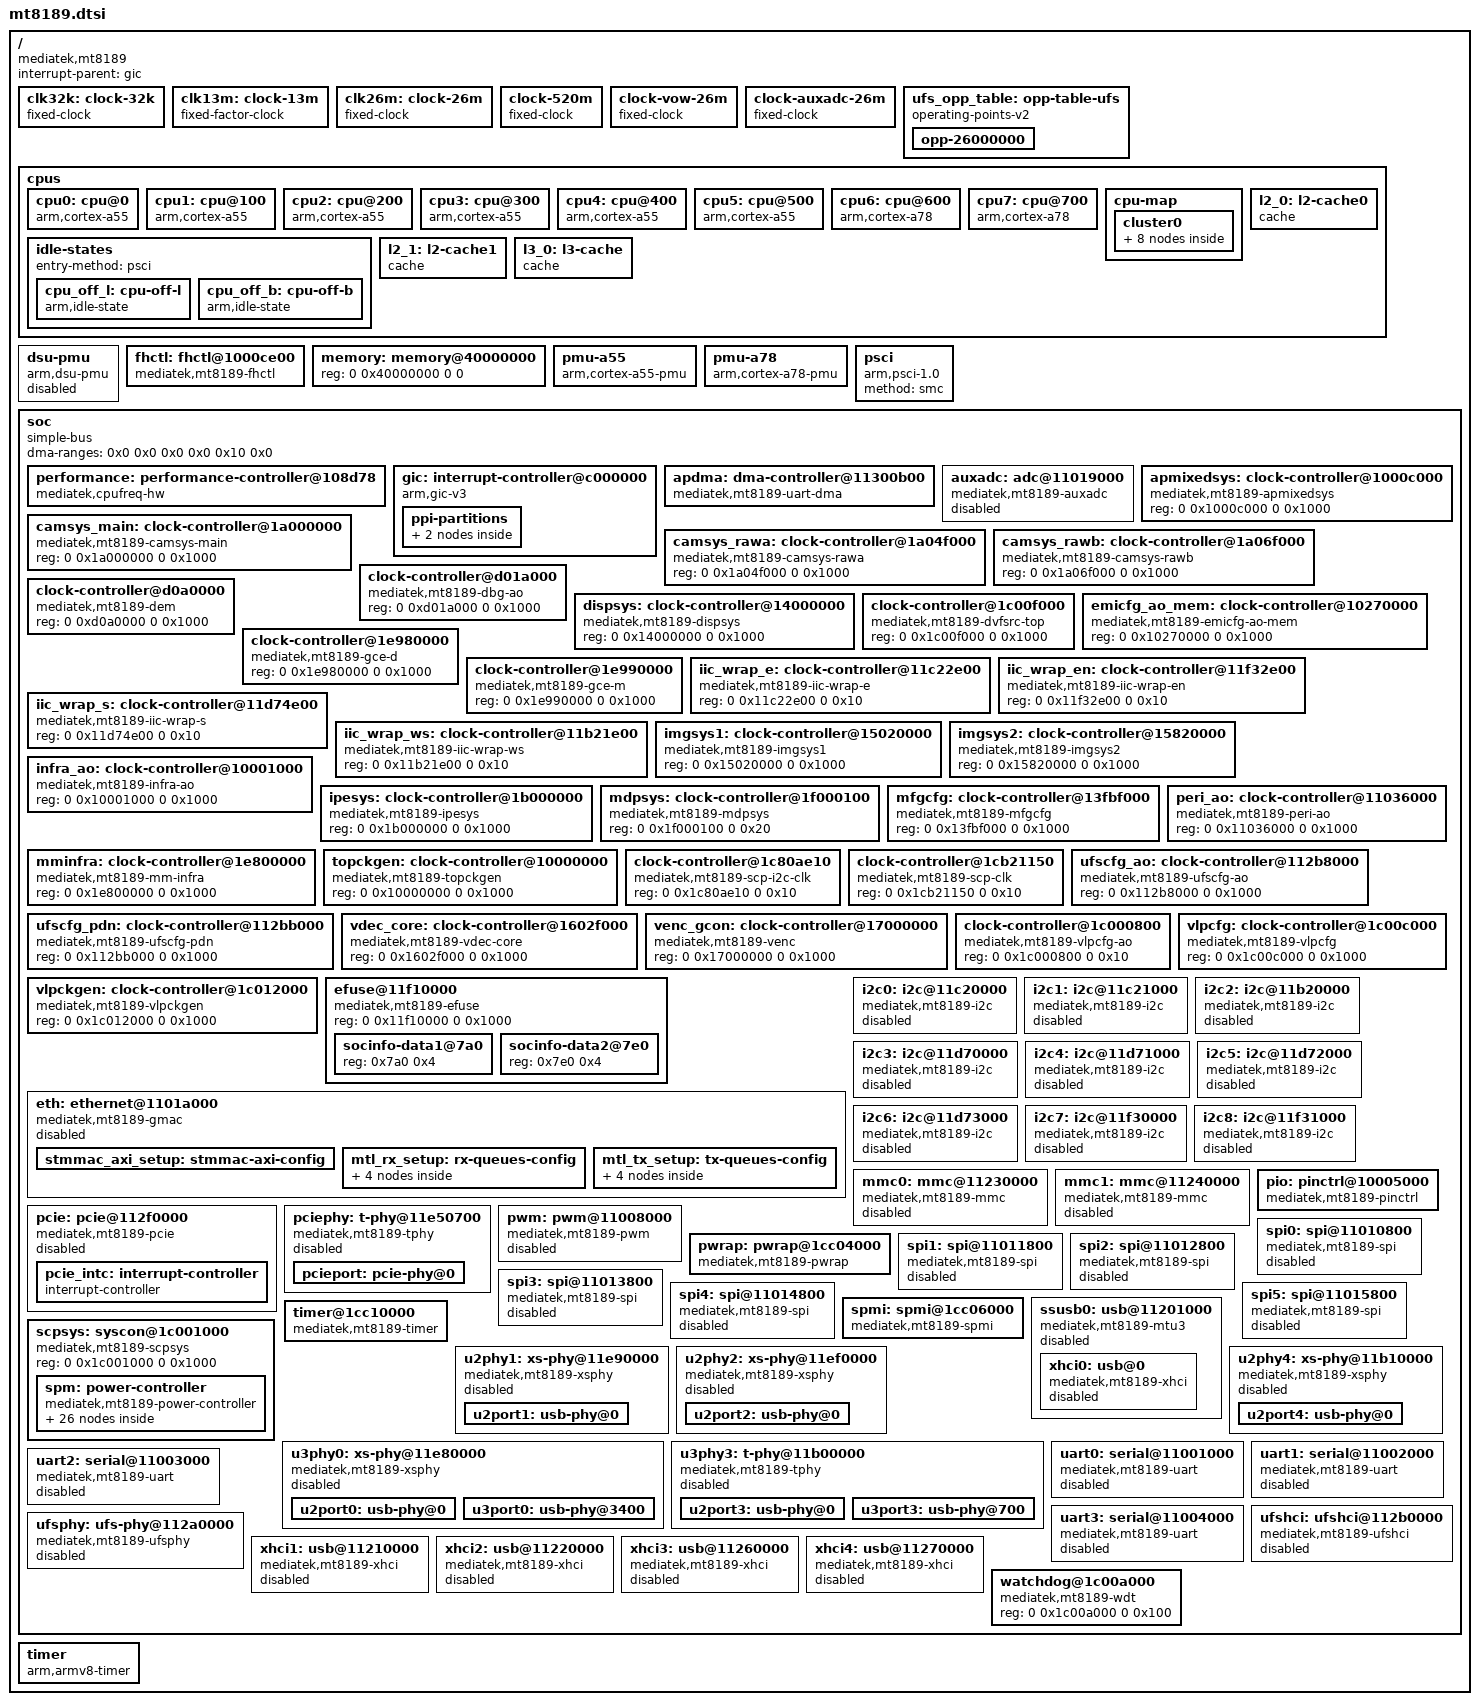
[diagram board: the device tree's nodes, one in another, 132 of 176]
// SPDX-License-Identifier: (GPL-2.0 OR MIT)
/*
 * Copyright (c) 2025 MediaTek Inc.
 *
 * Copyright (c) 2025 Collabora Ltd.
 * Author: Louis-Alexis Eyraud <louisalexis.eyraud@collabora.com>
 */

#include <dt-bindings/clock/mediatek,mt8189-clk.h>
#include <dt-bindings/interrupt-controller/arm-gic.h>
#include <dt-bindings/interrupt-controller/irq.h>
#include <dt-bindings/power/mediatek,mt8189-power.h>
#include <dt-bindings/phy/phy.h>
#include <dt-bindings/reset/mediatek,mt8189-resets.h>

/ {
	compatible = "mediatek,mt8189";
	interrupt-parent = <&gic>;
	#address-cells = <2>;
	#size-cells = <2>;

	clk32k: clock-32k {
		compatible = "fixed-clock";
		#clock-cells = <0>;
		clock-frequency = <32000>;
		clock-output-names = "clk32k";
	};

	clk13m: clock-13m {
		compatible = "fixed-factor-clock";
		#clock-cells = <0>;
		clocks = <&clk26m>;
		clock-mult = <1>;
		clock-div = <2>;
		clock-output-names = "clk13m";
	};

	clk26m: clock-26m {
		compatible = "fixed-clock";
		#clock-cells = <0>;
		clock-frequency = <26000000>;
		clock-output-names = "clk26m";
	};

	clock-520m {
		compatible = "fixed-clock";
		#clock-cells = <0>;
		clock-frequency = <520000000>;
		clock-output-names = "ulposc";
	};

	clock-vow-26m {
		compatible = "fixed-clock";
		#clock-cells = <0>;
		clock-frequency = <26000000>;
		clock-output-names = "vowpll";
	};

	clock-auxadc-26m {
		compatible = "fixed-clock";
		#clock-cells = <0>;
		clock-frequency = <26000000>;
		clock-output-names = "aud_adc_ext";
	};

	ufs_opp_table: opp-table-ufs {
		compatible = "operating-points-v2";

		opp-26000000 {
			opp-hz = /bits/ 64 <26000000>, /bits/ 64 <0>,
				 /bits/ 64 <0>, /bits/ 64 <0>, /bits/ 64 <0>,
				 /bits/ 64 <0>, /bits/ 64 <0>, /bits/ 64 <0>,
				 /bits/ 64 <0>, /bits/ 64 <0>, /bits/ 64 <0>,
				 /bits/ 64 <0>, /bits/ 64 <0>, /bits/ 64 <0>,
				 /bits/ 64 <0>, /bits/ 64 <0>;
		};
	};

	cpus {
		#address-cells = <1>;
		#size-cells = <0>;

		cpu0: cpu@0 {
			device_type = "cpu";
			compatible = "arm,cortex-a55";
			reg = <0x000>;
			enable-method = "psci";
			capacity-dmips-mhz = <282>;
			cpu-idle-states = <&cpu_off_l>;
			i-cache-size = <32768>;
			i-cache-line-size = <64>;
			i-cache-sets = <128>;
			d-cache-size = <32768>;
			d-cache-line-size = <64>;
			d-cache-sets = <128>;
			next-level-cache = <&l2_0>;
			performance-domains = <&performance 0>;
			#cooling-cells = <2>;
		};

		cpu1: cpu@100 {
			device_type = "cpu";
			compatible = "arm,cortex-a55";
			reg = <0x100>;
			enable-method = "psci";
			capacity-dmips-mhz = <282>;
			cpu-idle-states = <&cpu_off_l>;
			i-cache-size = <32768>;
			i-cache-line-size = <64>;
			i-cache-sets = <128>;
			d-cache-size = <32768>;
			d-cache-line-size = <64>;
			d-cache-sets = <128>;
			next-level-cache = <&l2_0>;
			performance-domains = <&performance 0>;
			#cooling-cells = <2>;
		};

		cpu2: cpu@200 {
			device_type = "cpu";
			compatible = "arm,cortex-a55";
			reg = <0x200>;
			enable-method = "psci";
			capacity-dmips-mhz = <282>;
			cpu-idle-states = <&cpu_off_l>;
			i-cache-size = <32768>;
			i-cache-line-size = <64>;
			i-cache-sets = <128>;
			d-cache-size = <32768>;
			d-cache-line-size = <64>;
			d-cache-sets = <128>;
			next-level-cache = <&l2_0>;
			performance-domains = <&performance 0>;
			#cooling-cells = <2>;
		};

		cpu3: cpu@300 {
			device_type = "cpu";
			compatible = "arm,cortex-a55";
			reg = <0x300>;
			enable-method = "psci";
			capacity-dmips-mhz = <282>;
			cpu-idle-states = <&cpu_off_l>;
			i-cache-size = <32768>;
			i-cache-line-size = <64>;
			i-cache-sets = <128>;
			d-cache-size = <32768>;
			d-cache-line-size = <64>;
			d-cache-sets = <128>;
			next-level-cache = <&l2_0>;
			performance-domains = <&performance 0>;
			#cooling-cells = <2>;
		};

		cpu4: cpu@400 {
			device_type = "cpu";
			compatible = "arm,cortex-a55";
			reg = <0x400>;
			enable-method = "psci";
			capacity-dmips-mhz = <282>;
			cpu-idle-states = <&cpu_off_l>;
			i-cache-size = <32768>;
			i-cache-line-size = <64>;
			i-cache-sets = <128>;
			d-cache-size = <32768>;
			d-cache-line-size = <64>;
			d-cache-sets = <128>;
			next-level-cache = <&l2_0>;
			performance-domains = <&performance 0>;
			#cooling-cells = <2>;
		};

		cpu5: cpu@500 {
			device_type = "cpu";
			compatible = "arm,cortex-a55";
			reg = <0x500>;
			enable-method = "psci";
			capacity-dmips-mhz = <282>;
			cpu-idle-states = <&cpu_off_l>;
			i-cache-size = <32768>;
			i-cache-line-size = <64>;
			i-cache-sets = <128>;
			d-cache-size = <32768>;
			d-cache-line-size = <64>;
			d-cache-sets = <128>;
			next-level-cache = <&l2_0>;
			performance-domains = <&performance 0>;
			#cooling-cells = <2>;
		};

		cpu6: cpu@600 {
			device_type = "cpu";
			compatible = "arm,cortex-a78";
			reg = <0x600>;
			enable-method = "psci";
			capacity-dmips-mhz = <1024>;
			cpu-idle-states = <&cpu_off_b>;
			i-cache-size = <65536>;
			i-cache-line-size = <64>;
			i-cache-sets = <256>;
			d-cache-size = <65536>;
			d-cache-line-size = <64>;
			d-cache-sets = <256>;
			next-level-cache = <&l2_1>;
			performance-domains = <&performance 1>;
			#cooling-cells = <2>;
		};

		cpu7: cpu@700 {
			device_type = "cpu";
			compatible = "arm,cortex-a78";
			reg = <0x700>;
			enable-method = "psci";
			capacity-dmips-mhz = <1024>;
			cpu-idle-states = <&cpu_off_b>;
			i-cache-size = <65536>;
			i-cache-line-size = <64>;
			i-cache-sets = <256>;
			d-cache-size = <65536>;
			d-cache-line-size = <64>;
			d-cache-sets = <256>;
			next-level-cache = <&l2_1>;
			performance-domains = <&performance 1>;
			#cooling-cells = <2>;
		};

		cpu-map {
			cluster0 {
				core0 {
					cpu = <&cpu0>;
				};

				core1 {
					cpu = <&cpu1>;
				};

				core2 {
					cpu = <&cpu2>;
				};

				core3 {
					cpu = <&cpu3>;
				};

				core4 {
					cpu = <&cpu4>;
				};

				core5 {
					cpu = <&cpu5>;
				};

				core6 {
					cpu = <&cpu6>;
				};

				core7 {
					cpu = <&cpu7>;
				};
			};
		};

		idle-states {
			entry-method = "psci";

			cpu_off_l: cpu-off-l {
				compatible = "arm,idle-state";
				arm,psci-suspend-param = <0x00010000>;
				local-timer-stop;
				entry-latency-us = <25>;
				exit-latency-us = <57>;
				min-residency-us = <5700>;
			};

			cpu_off_b: cpu-off-b {
				compatible = "arm,idle-state";
				arm,psci-suspend-param = <0x00010000>;
				local-timer-stop;
				entry-latency-us = <35>;
				exit-latency-us = <82>;
				min-residency-us = <1890>;
			};
		};

		l2_0: l2-cache0 {
			compatible = "cache";
			cache-level = <2>;
			cache-size = <131072>;
			cache-line-size = <64>;
			cache-sets = <512>;
			next-level-cache = <&l3_0>;
			cache-unified;
		};

		l2_1: l2-cache1 {
			compatible = "cache";
			cache-level = <2>;
			cache-size = <262144>;
			cache-line-size = <64>;
			cache-sets = <512>;
			next-level-cache = <&l3_0>;
			cache-unified;
		};

		l3_0: l3-cache {
			compatible = "cache";
			cache-level = <3>;
			cache-size = <1048576>;
			cache-line-size = <64>;
			cache-sets = <2048>;
			cache-unified;
		};
	};

	dsu-pmu {
		compatible = "arm,dsu-pmu";
		interrupts = <GIC_SPI 18 IRQ_TYPE_LEVEL_HIGH 0>;
		cpus = <&cpu0>, <&cpu1>, <&cpu2>, <&cpu3>,
		       <&cpu4>, <&cpu5>, <&cpu6>, <&cpu7>;
		status = "fail";
	};

	fhctl: fhctl@1000ce00 {
		compatible = "mediatek,mt8189-fhctl";
		clocks = <&apmixedsys CLK_APMIXED_APUPLL>,
			 <&apmixedsys CLK_APMIXED_APUPLL2>,
			 <&apmixedsys CLK_APMIXED_ARMPLL_LL>,
			 <&apmixedsys CLK_APMIXED_ARMPLL_BL>,
			 <&apmixedsys CLK_APMIXED_CCIPLL>,
			 <&apmixedsys CLK_APMIXED_EMIPLL>,
			 <&apmixedsys CLK_APMIXED_MAINPLL>,
			 <&apmixedsys CLK_APMIXED_MFGPLL>,
			 <&apmixedsys CLK_APMIXED_MMPLL>,
			 <&apmixedsys CLK_APMIXED_MSDCPLL>,
			 <&apmixedsys CLK_APMIXED_TVDPLL1>,
			 <&apmixedsys CLK_APMIXED_TVDPLL2>,
			 <&apmixedsys CLK_APMIXED_UFSPLL>;
		reg = <0 0x1000ce00 0 0x200>;
		status = "okay";
	};

	memory: memory@40000000 {
		device_type = "memory";
		/* This memory size is filled in by the bootloader */
		reg = <0 0x40000000 0 0>;
	};

	pmu-a55 {
		compatible = "arm,cortex-a55-pmu";
		interrupt-parent = <&gic>;
		interrupts = <GIC_PPI 7 IRQ_TYPE_LEVEL_HIGH &ppi_cluster0>;
	};

	pmu-a78 {
		compatible = "arm,cortex-a78-pmu";
		interrupt-parent = <&gic>;
		interrupts = <GIC_PPI 7 IRQ_TYPE_LEVEL_HIGH &ppi_cluster1>;
	};

	psci {
		compatible = "arm,psci-1.0";
		method = "smc";
	};

	soc {
		compatible = "simple-bus";
		#address-cells = <2>;
		#size-cells = <2>;
		ranges;
		dma-ranges = <0x0 0x0 0x0 0x0 0x10 0x0>;

		performance: performance-controller@108d78 {
			compatible = "mediatek,cpufreq-hw";
			reg = <0 0x00108d78 0 0x120>, <0 0x00108e98 0 0x120>;
			#performance-domain-cells = <1>;
		};

		gic: interrupt-controller@c000000 {
			compatible = "arm,gic-v3";
			reg = <0 0xc000000 0 0x40000>, /* distributor */
			      <0 0xc040000 0 0x200000>; /* redistributor */
			interrupt-parent = <&gic>;
			interrupts = <GIC_PPI 9 IRQ_TYPE_LEVEL_HIGH 0>;
			interrupt-controller;
			#interrupt-cells = <4>;
			#redistributor-regions = <1>;

			ppi-partitions {
				ppi_cluster0: interrupt-partition-0 {
					affinity = <&cpu0 &cpu1 &cpu2 &cpu3 &cpu4 &cpu5>;
				};

				ppi_cluster1: interrupt-partition-1 {
					affinity = <&cpu6 &cpu7>;
				};
			};
		};

		apdma: dma-controller@11300b00 {
			compatible = "mediatek,mt8189-uart-dma", "mediatek,mt6985-uart-dma";
			reg = <0 0x11300b00 0 0x80>,
			      <0 0x11300b80 0 0x80>,
			      <0 0x11300c00 0 0x80>,
			      <0 0x11300c80 0 0x80>,
			      <0 0x11300d00 0 0x80>,
			      <0 0x11300d80 0 0x80>,
			      <0 0x11300e00 0 0x80>,
			      <0 0x11300e80 0 0x80>;
			interrupts = <GIC_SPI 432 IRQ_TYPE_LEVEL_HIGH 0>,
				     <GIC_SPI 433 IRQ_TYPE_LEVEL_HIGH 0>,
				     <GIC_SPI 434 IRQ_TYPE_LEVEL_HIGH 0>,
				     <GIC_SPI 435 IRQ_TYPE_LEVEL_HIGH 0>,
				     <GIC_SPI 436 IRQ_TYPE_LEVEL_HIGH 0>,
				     <GIC_SPI 437 IRQ_TYPE_LEVEL_HIGH 0>,
				     <GIC_SPI 438 IRQ_TYPE_LEVEL_HIGH 0>,
				     <GIC_SPI 439 IRQ_TYPE_LEVEL_HIGH 0>;
			clocks = <&peri_ao CLK_PERAO_DMA_B>;
			clock-names = "apdma";
			dma-requests = <8>;
			#dma-cells = <1>;
		};

		auxadc: adc@11019000 {
			compatible = "mediatek,mt8189-auxadc", "mediatek,mt8173-auxadc";
			reg = <0 0x11019000 0 0x1000>;
			clocks = <&peri_ao CLK_PERAO_AUXADC_26M>;
			clock-names = "main";
			#io-channel-cells = <1>;
			status = "disabled";
		};

		apmixedsys: clock-controller@1000c000 {
			compatible = "mediatek,mt8189-apmixedsys", "syscon";
			reg = <0 0x1000c000 0 0x1000>;
			#clock-cells = <1>;
		};

		camsys_main: clock-controller@1a000000 {
			compatible = "mediatek,mt8189-camsys-main";
			reg = <0 0x1a000000 0 0x1000>;
			#clock-cells = <1>;
		};

		camsys_rawa: clock-controller@1a04f000 {
			compatible = "mediatek,mt8189-camsys-rawa";
			reg = <0 0x1a04f000 0 0x1000>;
			#clock-cells = <1>;
		};

		camsys_rawb: clock-controller@1a06f000 {
			compatible = "mediatek,mt8189-camsys-rawb";
			reg = <0 0x1a06f000 0 0x1000>;
			#clock-cells = <1>;
		};

		clock-controller@d01a000 {
			compatible = "mediatek,mt8189-dbg-ao";
			reg = <0 0xd01a000 0 0x1000>;
			#clock-cells = <1>;
		};

		clock-controller@d0a0000 {
			compatible = "mediatek,mt8189-dem";
			reg = <0 0xd0a0000 0 0x1000>;
			#clock-cells = <1>;
		};

		dispsys: clock-controller@14000000 {
			compatible = "mediatek,mt8189-dispsys";
			reg = <0 0x14000000 0 0x1000>;
			#clock-cells = <1>;
		};

		clock-controller@1c00f000 {
			compatible = "mediatek,mt8189-dvfsrc-top";
			reg = <0 0x1c00f000 0 0x1000>;
			#clock-cells = <1>;
		};

		emicfg_ao_mem: clock-controller@10270000 {
			compatible = "mediatek,mt8189-emicfg-ao-mem", "syscon";
			reg = <0 0x10270000 0 0x1000>;
			#clock-cells = <1>;
		};

		clock-controller@1e980000 {
			compatible = "mediatek,mt8189-gce-d";
			reg = <0 0x1e980000 0 0x1000>;
			#clock-cells = <1>;
		};

		clock-controller@1e990000 {
			compatible = "mediatek,mt8189-gce-m";
			reg = <0 0x1e990000 0 0x1000>;
			#clock-cells = <1>;
		};

		iic_wrap_e: clock-controller@11c22e00 {
			compatible = "mediatek,mt8189-iic-wrap-e";
			reg = <0 0x11c22e00 0 0x10>;
			#clock-cells = <1>;
		};

		iic_wrap_en: clock-controller@11f32e00 {
			compatible = "mediatek,mt8189-iic-wrap-en";
			reg = <0 0x11f32e00 0 0x10>;
			#clock-cells = <1>;
		};

		iic_wrap_s: clock-controller@11d74e00 {
			compatible = "mediatek,mt8189-iic-wrap-s";
			reg = <0 0x11d74e00 0 0x10>;
			#clock-cells = <1>;
		};

		iic_wrap_ws: clock-controller@11b21e00 {
			compatible = "mediatek,mt8189-iic-wrap-ws";
			reg = <0 0x11b21e00 0 0x10>;
			#clock-cells = <1>;
		};

		imgsys1: clock-controller@15020000 {
			compatible = "mediatek,mt8189-imgsys1";
			reg = <0 0x15020000 0 0x1000>;
			#clock-cells = <1>;
		};

		imgsys2: clock-controller@15820000 {
			compatible = "mediatek,mt8189-imgsys2";
			reg = <0 0x15820000 0 0x1000>;
			#clock-cells = <1>;
		};

		infra_ao: clock-controller@10001000 {
			compatible = "mediatek,mt8189-infra-ao", "syscon";
			reg = <0 0x10001000 0 0x1000>;
			#clock-cells = <1>;
		};

		ipesys: clock-controller@1b000000 {
			compatible = "mediatek,mt8189-ipesys";
			reg = <0 0x1b000000 0 0x1000>;
			#clock-cells = <1>;
		};

		mdpsys: clock-controller@1f000100 {
			compatible = "mediatek,mt8189-mdpsys";
			reg = <0 0x1f000100 0 0x20>;
			#clock-cells = <1>;
		};

		mfgcfg: clock-controller@13fbf000 {
			compatible = "mediatek,mt8189-mfgcfg";
			reg = <0 0x13fbf000 0 0x1000>;
			#clock-cells = <1>;
		};

		mminfra: clock-controller@1e800000 {
			compatible = "mediatek,mt8189-mm-infra";
			reg = <0 0x1e800000 0 0x1000>;
			#clock-cells = <1>;
		};

		peri_ao: clock-controller@11036000 {
			compatible = "mediatek,mt8189-peri-ao", "syscon";
			reg = <0 0x11036000 0 0x1000>;
			#clock-cells = <1>;
			#reset-cells = <1>;
		};

		topckgen: clock-controller@10000000 {
			compatible = "mediatek,mt8189-topckgen", "syscon";
			reg = <0 0x10000000 0 0x1000>;
			#clock-cells = <1>;
		};

		clock-controller@1c80ae10 {
			compatible = "mediatek,mt8189-scp-i2c-clk";
			reg = <0 0x1c80ae10 0 0x10>;
			#clock-cells = <1>;
		};

		clock-controller@1cb21150 {
			compatible = "mediatek,mt8189-scp-clk";
			reg = <0 0x1cb21150 0 0x10>;
			#clock-cells = <1>;
		};

		ufscfg_ao: clock-controller@112b8000 {
			compatible = "mediatek,mt8189-ufscfg-ao";
			reg = <0 0x112b8000 0 0x1000>;
			#clock-cells = <1>;
			#reset-cells = <1>;
		};

		ufscfg_pdn: clock-controller@112bb000 {
			compatible = "mediatek,mt8189-ufscfg-pdn";
			reg = <0 0x112bb000 0 0x1000>;
			#clock-cells = <1>;
			#reset-cells = <1>;
		};

		vdec_core: clock-controller@1602f000 {
			compatible = "mediatek,mt8189-vdec-core";
			reg = <0 0x1602f000 0 0x1000>;
			#clock-cells = <1>;
		};

		venc_gcon: clock-controller@17000000 {
			compatible = "mediatek,mt8189-venc";
			reg = <0 0x17000000 0 0x1000>;
			#clock-cells = <1>;
		};

		clock-controller@1c000800 {
			compatible = "mediatek,mt8189-vlpcfg-ao";
			reg = <0 0x1c000800 0 0x10>;
			#clock-cells = <1>;
		};

		vlpcfg: clock-controller@1c00c000 {
			compatible = "mediatek,mt8189-vlpcfg";
			reg = <0 0x1c00c000 0 0x1000>;
			#clock-cells = <1>;
		};

		vlpckgen: clock-controller@1c012000 {
			compatible = "mediatek,mt8189-vlpckgen", "syscon";
			reg = <0 0x1c012000 0 0x1000>;
			#clock-cells = <1>;
		};

		efuse@11f10000 {
			compatible = "mediatek,mt8189-efuse", "mediatek,mt8186-efuse";
			reg = <0 0x11f10000 0 0x1000>;
			#address-cells = <1>;
			#size-cells = <1>;

			socinfo-data1@7a0 {
				reg = <0x7a0 0x4>;
			};

			socinfo-data2@7e0 {
				reg = <0x7e0 0x4>;
			};
		};

		eth: ethernet@1101a000 {
			compatible = "mediatek,mt8189-gmac", "snps,dwmac-5.10a";
			reg = <0 0x1101a000 0 0x4000>;
			assigned-clocks = <&topckgen CLK_TOP_ETH_250M_SEL>,
					  <&topckgen CLK_TOP_ETH_62P4M_PTP_SEL>,
					  <&topckgen CLK_TOP_ETH_50M_RMII_SEL>;
			assigned-clock-parents = <&topckgen CLK_TOP_ETHPLL_D2>,
						 <&topckgen CLK_TOP_ETHPLL_D8>,
						 <&topckgen CLK_TOP_ETHPLL_D10>;
			clocks = <&topckgen CLK_TOP_ETH_250M_SEL>,
				 <&topckgen CLK_TOP_ETH_62P4M_PTP_SEL>,
				 <&topckgen CLK_TOP_ETH_50M_RMII_SEL>;
			clock-names = "mac_main", "ptp_ref", "rmii_internal";
			interrupts = <GIC_SPI 475 IRQ_TYPE_LEVEL_HIGH 0>;
			interrupt-names = "macirq";
			power-domains = <&spm MT8189_POWER_DOMAIN_PCIE>;
			mediatek,pericfg = <&peri_ao>;
			snps,axi-config = <&stmmac_axi_setup>;
			snps,mtl-rx-config = <&mtl_rx_setup>;
			snps,mtl-tx-config = <&mtl_tx_setup>;
			snps,txpbl = <16>;
			snps,rxpbl = <16>;
			snps,clk-csr = <0>;
			status = "disabled";

			stmmac_axi_setup: stmmac-axi-config {
				snps,blen = <0 0 0 0 16 8 4>;
				snps,rd_osr_lmt = <0x7>;
				snps,wr_osr_lmt = <0x7>;
			};

			mtl_rx_setup: rx-queues-config {
				snps,rx-queues-to-use = <4>;
				snps,rx-sched-sp;

				queue0 {
					snps,dcb-algorithm;
					snps,map-to-dma-channel = <0x0>;
				};

				queue1 {
					snps,dcb-algorithm;
					snps,map-to-dma-channel = <0x0>;
				};

				queue2 {
					snps,dcb-algorithm;
					snps,map-to-dma-channel = <0x0>;
				};

				queue3 {
					snps,dcb-algorithm;
					snps,map-to-dma-channel = <0x0>;
				};
			};

			mtl_tx_setup: tx-queues-config {
				snps,tx-queues-to-use = <4>;
				snps,tx-sched-wrr;

				queue0 {
					snps,dcb-algorithm;
					snps,priority = <0x0>;
					snps,weight = <0x10>;
				};

				queue1 {
					snps,dcb-algorithm;
					snps,priority = <0x1>;
					snps,weight = <0x11>;
				};

				queue2 {
					snps,dcb-algorithm;
					snps,priority = <0x2>;
					snps,weight = <0x12>;
				};

				queue3 {
					snps,dcb-algorithm;
					snps,priority = <0x3>;
					snps,weight = <0x13>;
				};
			};
		};

		i2c0: i2c@11c20000 {
			compatible = "mediatek,mt8189-i2c", "mediatek,mt8188-i2c";
			reg = <0 0x11c20000 0 0x1000>, <0 0x11300200 0 0x80>;
			#address-cells = <1>;
			clock-div = <1>;
			clocks = <&iic_wrap_e CLK_IMPE_I2C0>, <&peri_ao CLK_PERAO_DMA_B>;
			clock-names = "main", "dma";
			interrupts = <GIC_SPI 274 IRQ_TYPE_LEVEL_HIGH 0>;
			#size-cells = <0>;
			status = "disabled";
		};

		i2c1: i2c@11c21000 {
			compatible = "mediatek,mt8189-i2c", "mediatek,mt8188-i2c";
			reg = <0 0x11c21000 0 0x1000>, <0 0x11300300 0 0x80>;
			#address-cells = <1>;
			clock-div = <1>;
			clocks = <&iic_wrap_e CLK_IMPE_I2C1>, <&peri_ao CLK_PERAO_DMA_B>;
			clock-names = "main", "dma";
			interrupts = <GIC_SPI 275 IRQ_TYPE_LEVEL_HIGH 0>;
			#size-cells = <0>;
			status = "disabled";
		};

		i2c2: i2c@11b20000 {
			compatible = "mediatek,mt8189-i2c", "mediatek,mt8188-i2c";
			reg = <0 0x11b20000 0 0x1000>, <0 0x11300400 0 0x80>;
			#address-cells = <1>;
			clock-div = <1>;
			clocks = <&iic_wrap_ws CLK_IMPWS_I2C2>, <&peri_ao CLK_PERAO_DMA_B>;
			clock-names = "main", "dma";
			interrupts = <GIC_SPI 276 IRQ_TYPE_LEVEL_HIGH 0>;
			#size-cells = <0>;
			status = "disabled";
		};

		i2c3: i2c@11d70000 {
			compatible = "mediatek,mt8189-i2c", "mediatek,mt8188-i2c";
			reg = <0 0x11d70000 0 0x1000>, <0 0x11300500 0 0x80>;
			#address-cells = <1>;
			clock-div = <1>;
			clocks = <&iic_wrap_s CLK_IMPS_I2C3>, <&peri_ao CLK_PERAO_DMA_B>;
			clock-names = "main", "dma";
			interrupts = <GIC_SPI 277 IRQ_TYPE_LEVEL_HIGH 0>;
			#size-cells = <0>;
			status = "disabled";
		};

		i2c4: i2c@11d71000 {
			compatible = "mediatek,mt8189-i2c", "mediatek,mt8188-i2c";
			reg = <0 0x11d71000 0 0x1000>, <0 0x11300600 0 0x80>;
			#address-cells = <1>;
			clock-div = <1>;
			clocks = <&iic_wrap_s CLK_IMPS_I2C4>, <&peri_ao CLK_PERAO_DMA_B>;
			clock-names = "main", "dma";
			interrupts = <GIC_SPI 208 IRQ_TYPE_LEVEL_HIGH 0>;
			#size-cells = <0>;
			status = "disabled";
		};

		i2c5: i2c@11d72000 {
			compatible = "mediatek,mt8189-i2c", "mediatek,mt8188-i2c";
			reg = <0 0x11d72000 0 0x1000>, <0 0x11300700 0 0x80>;
			#address-cells = <1>;
			clock-div = <1>;
			clocks = <&iic_wrap_s CLK_IMPS_I2C5>, <&peri_ao CLK_PERAO_DMA_B>;
			clock-names = "main", "dma";
			interrupts = <GIC_SPI 209 IRQ_TYPE_LEVEL_HIGH 0>;
			#size-cells = <0>;
			status = "disabled";
		};

		i2c6: i2c@11d73000 {
			compatible = "mediatek,mt8189-i2c", "mediatek,mt8188-i2c";
			reg = <0 0x11d73000 0 0x1000>, <0 0x11300800 0 0x80>;
			#address-cells = <1>;
			clock-div = <1>;
			clocks = <&iic_wrap_s CLK_IMPS_I2C6>, <&peri_ao CLK_PERAO_DMA_B>;
			clock-names = "main", "dma";
			interrupts = <GIC_SPI 210 IRQ_TYPE_LEVEL_HIGH 0>;
			#size-cells = <0>;
			status = "disabled";
		};

		i2c7: i2c@11f30000 {
			compatible = "mediatek,mt8189-i2c", "mediatek,mt8188-i2c";
			reg = <0 0x11f30000 0 0x1000>, <0 0x11300900 0 0x80>;
			#address-cells = <1>;
			clock-div = <1>;
			clocks = <&iic_wrap_en CLK_IMPEN_I2C7>, <&peri_ao CLK_PERAO_DMA_B>;
			clock-names = "main", "dma";
			interrupts = <GIC_SPI 211 IRQ_TYPE_LEVEL_HIGH 0>;
			#size-cells = <0>;
			status = "disabled";
		};

		i2c8: i2c@11f31000 {
			compatible = "mediatek,mt8189-i2c", "mediatek,mt8188-i2c";
			reg = <0 0x11f31000 0 0x1000>, <0 0x11300a00 0 0x80>;
			#address-cells = <1>;
			clock-div = <1>;
			clocks = <&iic_wrap_en CLK_IMPEN_I2C8>, <&peri_ao CLK_PERAO_DMA_B>;
			clock-names = "main", "dma";
			interrupts = <GIC_SPI 212 IRQ_TYPE_LEVEL_HIGH 0>;
			#size-cells = <0>;
			status = "disabled";
		};

		mmc0: mmc@11230000 {
			compatible = "mediatek,mt8189-mmc";
			reg = <0 0x11230000 0 0x10000>, <0 0x11e70000 0 0x1000>;
			clocks = <&topckgen CLK_TOP_MSDC50_0_SEL>,
				 <&peri_ao CLK_PERAO_MSDC0_H>,
				 <&peri_ao CLK_PERAO_MSDC0>,
				 <&topckgen CLK_TOP_MSDC50_0_HCLK_SEL>,
				 <&peri_ao CLK_PERAO_MSDC0_SLV_H>,
				 <&peri_ao CLK_PERAO_MSDC0_MST_F>;
			clock-names = "source", "hclk", "source_cg",
				      "bus_clk", "pclk_cg", "axi_cg";
			interrupts = <GIC_SPI 387 IRQ_TYPE_LEVEL_HIGH 0>;
			status = "disabled";
		};

		mmc1: mmc@11240000 {
			compatible = "mediatek,mt8189-mmc";
			reg = <0 0x11240000 0 0x1000>, <0 0x11d80000 0 0x1000>;
			clocks = <&topckgen CLK_TOP_MSDC30_1_SEL>,
				 <&peri_ao CLK_PERAO_MSDC1_H>,
				 <&peri_ao CLK_PERAO_MSDC1>,
				 <&topckgen CLK_TOP_MSDC30_1_HCLK_SEL>,
				 <&peri_ao CLK_PERAO_MSDC1_SLV_H>,
				 <&peri_ao CLK_PERAO_MSDC1_MST_F>;
			clock-names = "source", "hclk", "source_cg",
				      "bus_clk", "pclk_cg", "axi_cg";
			interrupts = <GIC_SPI 388 IRQ_TYPE_LEVEL_HIGH 0>;
			status = "disabled";
		};

		pcie: pcie@112f0000 {
			compatible = "mediatek,mt8189-pcie", "mediatek,mt8192-pcie";
			reg = <0 0x112f0000 0 0x4000>;
			reg-names = "pcie-mac";
			ranges = <0x82000000 0 0x30000000 0x0 0x30000000 0 0x04000000>;
			bus-range = <0x00 0xff>;
			device_type = "pci";
			linux,pci-domain = <0>;
			#address-cells = <3>;
			#size-cells = <2>;
			clocks = <&peri_ao CLK_PERAO_AHB_APB>,
				 <&topckgen CLK_TOP_F26M_CK_EN>,
				 <&peri_ao CLK_PERAO_TL>,
				 <&clk32k>,
				 <&peri_ao CLK_PERAO_REF>,
				 <&peri_ao CLK_PERAO_AXI>;
			clock-names = "pl_250m", "tl_26m", "tl_96m",
				      "tl_32k", "peri_26m", "peri_mem";
			#interrupt-cells = <1>;
			interrupts = <GIC_SPI 467 IRQ_TYPE_LEVEL_HIGH 0>;
			interrupt-map = <0 0 0 1 &pcie_intc 0>,
					<0 0 0 2 &pcie_intc 1>,
					<0 0 0 3 &pcie_intc 2>,
					<0 0 0 4 &pcie_intc 3>;
			interrupt-map-mask = <0 0 0 7>;
			phys = <&pcieport PHY_TYPE_PCIE>;
			phy-names = "pcie-phy";
			power-domains = <&spm MT8189_POWER_DOMAIN_PCIE>;
			status = "disabled";

			pcie_intc: interrupt-controller {
				#address-cells = <0>;
				#interrupt-cells = <1>;
				interrupt-controller;
			};
		};

		pciephy: t-phy@11e50700 {
			compatible = "mediatek,mt8189-tphy", "mediatek,generic-tphy-v3";
			ranges = <0x0 0x0 0x11e50700 0x700>;
			#address-cells = <1>;
			#size-cells = <1>;
			power-domains = <&spm MT8189_POWER_DOMAIN_PCIE_PHY>;
			status = "disabled";

			pcieport: pcie-phy@0 {
				reg = <0 0x700>;
				clocks = <&topckgen CLK_TOP_SSPXTP_F26M_CK_EN>;
				clock-names = "ref";
				#phy-cells = <1>;
			};
		};

		pio: pinctrl@10005000 {
			compatible = "mediatek,mt8189-pinctrl";
			reg = <0 0x10005000 0 0x1000>,
			      <0 0x11b50000 0 0x1000>,
			      <0 0x11c50000 0 0x1000>,
			      <0 0x11c60000 0 0x1000>,
			      <0 0x11d20000 0 0x1000>,
			      <0 0x11d30000 0 0x1000>,
			      <0 0x11d40000 0 0x1000>,
			      <0 0x11e20000 0 0x1000>,
			      <0 0x11e30000 0 0x1000>,
			      <0 0x11f20000 0 0x1000>,
			      <0 0x11ce0000 0 0x1000>,
			      <0 0x11de0000 0 0x1000>,
			      <0 0x11e60000 0 0x1000>,
			      <0 0x1c01e000 0 0x1000>,
			      <0 0x11f00000 0 0x1000>;
			reg-names = "base", "lm", "rb0", "rb1", "bm0", "bm1",
				    "bm2", "lt0", "lt1", "rt", "eint0", "eint1",
				    "eint2", "eint3", "eint4";
			gpio-controller;
			#gpio-cells = <2>;
			gpio-ranges = <&pio 0 0 182>;
			interrupt-controller;
			interrupts = <GIC_SPI 239 IRQ_TYPE_LEVEL_HIGH 0>;
			#interrupt-cells = <2>;
		};

		pwm: pwm@11008000 {
			compatible = "mediatek,mt8189-pwm";
			reg = <0 0x11008000 0 0x1000>;
			clocks = <&peri_ao CLK_PERAO_PWM_H>,
				 <&peri_ao CLK_PERAO_PWM_B>,
				 <&peri_ao CLK_PERAO_PWM_FB1>,
				 <&peri_ao CLK_PERAO_PWM_FB2>,
				 <&peri_ao CLK_PERAO_PWM_FB3>;
			clock-names = "top", "main", "pwm1", "pwm2", "pwm3";
			#pwm-cells = <2>;
			status = "disabled";
		};

		pwrap: pwrap@1cc04000 {
			compatible = "mediatek,mt8189-pwrap", "mediatek,mt8195-pwrap", "syscon";
			reg = <0 0x1cc04000 0 0x1000>;
			reg-names = "pwrap";
			assigned-clocks = <&vlpckgen CLK_VLP_CK_PWRAP_ULPOSC_SEL>;
			assigned-clock-parents = <&topckgen CLK_TOP_OSC_D10>;
			clocks =  <&vlpcfg CLK_VLPCFG_REG_PMIF_SPMI_M_SYS>,
				  <&vlpcfg CLK_VLPCFG_REG_PMIF_SPMI_M_TMR>;
			clock-names = "spi", "wrap";
			interrupts = <GIC_SPI 496 IRQ_TYPE_LEVEL_HIGH 0>;
		};

		spi0: spi@11010800 {
			compatible = "mediatek,mt8189-spi";
			reg = <0 0x11010800 0 0x100>;
			interrupts = <GIC_SPI 459 IRQ_TYPE_LEVEL_HIGH 0>;
			clocks = <&topckgen CLK_TOP_UNIVPLL_D6_D2>,
				 <&topckgen CLK_TOP_SPI0_SEL>,
				 <&peri_ao CLK_PERAO_SPI0_B>,
				 <&peri_ao CLK_PERAO_SPI0_H>;
			clock-names = "parent-clk", "sel-clk", "spi-clk", "hclk";
			#address-cells = <1>;
			#size-cells = <0>;
			status = "disabled";
		};

		spi1: spi@11011800 {
			compatible = "mediatek,mt8189-spi";
			reg = <0 0x11011800 0 0x100>;
			interrupts = <GIC_SPI 460 IRQ_TYPE_LEVEL_HIGH 0>;
			clocks = <&topckgen CLK_TOP_UNIVPLL_D6_D2>,
				 <&topckgen CLK_TOP_SPI1_SEL>,
				 <&peri_ao CLK_PERAO_SPI1_B>,
				 <&peri_ao CLK_PERAO_SPI1_H>;
			clock-names = "parent-clk", "sel-clk", "spi-clk", "hclk";
			#address-cells = <1>;
			#size-cells = <0>;
			status = "disabled";
		};

		spi2: spi@11012800 {
			compatible = "mediatek,mt8189-spi";
			reg = <0 0x11012800 0 0x100>;
			interrupts = <GIC_SPI 461 IRQ_TYPE_LEVEL_HIGH 0>;
			clocks = <&topckgen CLK_TOP_UNIVPLL_D6_D2>,
				 <&topckgen CLK_TOP_SPI2_SEL>,
				 <&peri_ao CLK_PERAO_SPI2_B>,
				 <&peri_ao CLK_PERAO_SPI2_H>;
			clock-names = "parent-clk", "sel-clk", "spi-clk", "hclk";
			#address-cells = <1>;
			#size-cells = <0>;
			status = "disabled";
		};

		spi3: spi@11013800 {
			compatible = "mediatek,mt8189-spi";
			reg = <0 0x11013800 0 0x100>;
			interrupts = <GIC_SPI 462 IRQ_TYPE_LEVEL_HIGH 0>;
			clocks = <&topckgen CLK_TOP_UNIVPLL_D6_D2>,
				 <&topckgen CLK_TOP_SPI3_SEL>,
				 <&peri_ao CLK_PERAO_SPI3_B>,
				 <&peri_ao CLK_PERAO_SPI3_H>;
			clock-names = "parent-clk", "sel-clk", "spi-clk", "hclk";
			#address-cells = <1>;
			#size-cells = <0>;
			status = "disabled";
		};

		spi4: spi@11014800 {
			compatible = "mediatek,mt8189-spi";
			reg = <0 0x11014800 0 0x100>;
			interrupts = <GIC_SPI 463 IRQ_TYPE_LEVEL_HIGH 0>;
			clocks = <&topckgen CLK_TOP_UNIVPLL_D6_D2>,
				 <&topckgen CLK_TOP_SPI4_SEL>,
				 <&peri_ao CLK_PERAO_SPI4_B>,
				 <&peri_ao CLK_PERAO_SPI4_H>;
			clock-names = "parent-clk", "sel-clk", "spi-clk", "hclk";
			#address-cells = <1>;
			#size-cells = <0>;
			status = "disabled";
		};

		spi5: spi@11015800 {
			compatible = "mediatek,mt8189-spi";
			reg = <0 0x11015800 0 0x100>;
			interrupts = <GIC_SPI 464 IRQ_TYPE_LEVEL_HIGH 0>;
			clocks = <&topckgen CLK_TOP_UNIVPLL_D6_D2>,
				 <&topckgen CLK_TOP_SPI5_SEL>,
				 <&peri_ao CLK_PERAO_SPI5_B>,
				 <&peri_ao CLK_PERAO_SPI5_H>;
			clock-names = "parent-clk", "sel-clk", "spi-clk", "hclk";
			#address-cells = <1>;
			#size-cells = <0>;
			status = "disabled";
		};

		spmi: spmi@1cc06000 {
			compatible = "mediatek,mt8189-spmi", "mediatek,mt8195-spmi";
			reg = <0 0x1cc06000 0 0x0008ff>, <0 0x1cc00000 0 0x000100>;
			reg-names = "pmif", "spmimst";
			clocks = <&vlpcfg CLK_VLPCFG_REG_PMIF_SPMI_P_SYS>,
				 <&vlpcfg CLK_VLPCFG_REG_PMIF_SPMI_P_TMR>,
				 <&vlpckgen CLK_VLP_CK_SPMI_P_MST_SEL>;
			clock-names = "pmif_sys_ck", "pmif_tmr_ck", "spmimst_clk_mux";
			#address-cells = <2>;
			#size-cells = <0>;
		};

		scpsys: syscon@1c001000 {
			compatible = "mediatek,mt8189-scpsys", "syscon", "simple-mfd";
			reg = <0 0x1c001000 0 0x1000>;

			/* System Power Manager */
			spm: power-controller {
				compatible = "mediatek,mt8189-power-controller";
				#address-cells = <1>;
				#size-cells = <0>;
				#power-domain-cells = <1>;

				mfg0: power-domain@MT8189_POWER_DOMAIN_MFG0 {
					reg = <MT8189_POWER_DOMAIN_MFG0>;
					#address-cells = <1>;
					#size-cells = <0>;
					#power-domain-cells = <1>;

					mfg1: power-domain@MT8189_POWER_DOMAIN_MFG1 {
						reg = <MT8189_POWER_DOMAIN_MFG1>;
						clocks = <&apmixedsys CLK_APMIXED_MFGPLL>,
							 <&topckgen CLK_TOP_MFG_REF_SEL>;
						clock-names = "mfg", "alt";
						#address-cells = <1>;
						#size-cells = <0>;
						#power-domain-cells = <1>;
						mediatek,infracfg = <&infra_ao>;
						mediatek,smi = <&emicfg_ao_mem>;

						power-domain@MT8189_POWER_DOMAIN_MFG2 {
							reg = <MT8189_POWER_DOMAIN_MFG2>;
							#power-domain-cells = <0>;
						};

						power-domain@MT8189_POWER_DOMAIN_MFG3 {
							reg = <MT8189_POWER_DOMAIN_MFG3>;
							#power-domain-cells = <0>;
						};
					};
				};

				/* power domain of the SoC */
				power-domain@MT8189_POWER_DOMAIN_CONN {
					reg = <MT8189_POWER_DOMAIN_CONN>;
					mediatek,infracfg = <&infra_ao>;
					#power-domain-cells = <0>;
				};

				power-domain@MT8189_POWER_DOMAIN_AUDIO {
					reg = <MT8189_POWER_DOMAIN_AUDIO>;
					clocks = <&topckgen CLK_TOP_AUD_INTBUS_SEL>;
					clock-names = "audio";
					mediatek,infracfg = <&infra_ao>;
					#power-domain-cells = <0>;
				};

				power-domain@MT8189_POWER_DOMAIN_ADSP_AO {
					reg = <MT8189_POWER_DOMAIN_ADSP_AO>;
					clocks = <&vlpckgen CLK_VLP_CK_VADSP_SEL>;
					clock-names = "vadsp";
					#address-cells = <1>;
					#size-cells = <0>;
					#power-domain-cells = <1>;

					power-domain@MT8189_POWER_DOMAIN_ADSP_INFRA {
						reg = <MT8189_POWER_DOMAIN_ADSP_INFRA>;
						#address-cells = <1>;
						#size-cells = <0>;
						#power-domain-cells = <1>;

						power-domain@MT8189_POWER_DOMAIN_ADSP_TOP_DORMANT {
							reg = <MT8189_POWER_DOMAIN_ADSP_TOP_DORMANT>;
							#power-domain-cells = <0>;
						};
					};
				};

				power-domain@MT8189_POWER_DOMAIN_MM_INFRA {
					reg = <MT8189_POWER_DOMAIN_MM_INFRA>;
					clocks = <&topckgen CLK_TOP_MMINFRA_SEL>,
						 <&mminfra CLK_MMINFRA_SMI>;
					clock-names = "mminfra", "ss-mminfra";
					mediatek,infracfg = <&infra_ao>;
					#address-cells = <1>;
					#size-cells = <0>;
					#power-domain-cells = <1>;

					power-domain@MT8189_POWER_DOMAIN_ISP_IMG1 {
						reg = <MT8189_POWER_DOMAIN_ISP_IMG1>;
						clocks = <&topckgen CLK_TOP_IMG1_SEL>,
							 <&imgsys1 CLK_IMGSYS1_LARB9>,
							 <&imgsys1 CLK_IMGSYS1_LARB11>,
							 <&imgsys1 CLK_IMGSYS1_GALS>;
						clock-names = "img1", "ss-img1-0", "ss-img1-1", "ss-img1-2";
						mediatek,infracfg = <&infra_ao>;
						#address-cells = <1>;
						#size-cells = <0>;
						#power-domain-cells = <1>;

						power-domain@MT8189_POWER_DOMAIN_ISP_IMG2 {
							reg = <MT8189_POWER_DOMAIN_ISP_IMG2>;
							clocks = <&imgsys2 CLK_IMGSYS2_LARB9>,
								 <&imgsys2 CLK_IMGSYS2_LARB11>,
								 <&imgsys2 CLK_IMGSYS2_GALS>;
							clock-names = "ss-img2-0", "ss-img2-1", "ss-img2-2";
							#power-domain-cells = <0>;
						};
					};

					power-domain@MT8189_POWER_DOMAIN_ISP_IPE {
						reg = <MT8189_POWER_DOMAIN_ISP_IPE>;
						clocks = <&topckgen CLK_TOP_IPE_SEL>,
							 <&ipesys CLK_IPE_LARB19>,
							 <&ipesys CLK_IPE_LARB20>,
							 <&ipesys CLK_IPE_SMI_SUBCOM>,
							 <&ipesys CLK_IPESYS_GALS>;
						clock-names = "ipe", "ss-ipe0", "ss-ipe1", "ss-ipe2", "ss-ipe3";
						mediatek,infracfg = <&infra_ao>;
						#power-domain-cells = <0>;
					};

					power-domain@MT8189_POWER_DOMAIN_VDE0 {
						reg = <MT8189_POWER_DOMAIN_VDE0>;
						clocks = <&topckgen CLK_TOP_VDEC_SEL>,
							 <&vdec_core CLK_VDEC_CORE_LARB_CKEN>;
						clock-names = "vdec", "ss-vdec";
						mediatek,infracfg = <&infra_ao>;
						#power-domain-cells = <0>;
					};

					power-domain@MT8189_POWER_DOMAIN_VEN0 {
						reg = <MT8189_POWER_DOMAIN_VEN0>;
						clocks = <&topckgen CLK_TOP_VENC_SEL>,
							 <&venc_gcon CLK_VEN1_CKE0_LARB>;
						clock-names = "venc", "ss-venc";
						mediatek,infracfg = <&infra_ao>;
						#power-domain-cells = <0>;
					};

					power-domain@MT8189_POWER_DOMAIN_CAM_MAIN {
						reg = <MT8189_POWER_DOMAIN_CAM_MAIN>;
						clocks = <&topckgen CLK_TOP_CAM_SEL>,
							 <&camsys_main CLK_CAM_M_LARB13>,
							 <&camsys_main CLK_CAM_M_LARB14>,
							 <&camsys_main CLK_CAM_M_CAM2MM_GALS>;
						clock-names = "cam", "ss-cam0", "ss-cam1", "ss-cam2";
						mediatek,infracfg = <&infra_ao>;
						#address-cells = <1>;
						#size-cells = <0>;
						#power-domain-cells = <1>;

						power-domain@MT8189_POWER_DOMAIN_CAM_SUBA {
							reg = <MT8189_POWER_DOMAIN_CAM_SUBA>;
							clocks = <&camsys_rawa CLK_CAM_RA_CAMSYS_RAWA_LARBX>;
							clock-names = "ss-cam-suba";
							#power-domain-cells = <0>;
						};

						power-domain@MT8189_POWER_DOMAIN_CAM_SUBB {
							reg = <MT8189_POWER_DOMAIN_CAM_SUBB>;
							clocks = <&camsys_rawb CLK_CAM_RB_CAMSYS_RAWB_LARBX>;
							clock-names = "ss-cam-subb";
							#power-domain-cells = <0>;
						};
					};

					power-domain@MT8189_POWER_DOMAIN_MDP0 {
						reg = <MT8189_POWER_DOMAIN_MDP0>;
						clocks = <&topckgen CLK_TOP_MDP0_SEL>,
							 <&mdpsys CLK_MDP_SMI0>;
						clock-names = "mdp", "ss-mdp";
						mediatek,infracfg = <&infra_ao>;
						#power-domain-cells = <0>;
					};

					power-domain@MT8189_POWER_DOMAIN_DISP {
						reg = <MT8189_POWER_DOMAIN_DISP>;
						clocks = <&topckgen CLK_TOP_DISP0_SEL>,
							 <&dispsys CLK_MM_SMI_LARB>;
						clock-names = "disp", "ss-disp";
						mediatek,infracfg = <&infra_ao>;
						#address-cells = <1>;
						#size-cells = <0>;
						#power-domain-cells = <1>;

						power-domain@MT8189_POWER_DOMAIN_DP_TX {
							reg = <MT8189_POWER_DOMAIN_DP_TX>;
							#address-cells = <1>;
							#size-cells = <0>;
							#power-domain-cells = <1>;

							power-domain@MT8189_POWER_DOMAIN_EDP_TX_DORMANT {
								reg = <MT8189_POWER_DOMAIN_EDP_TX_DORMANT>;
								#power-domain-cells = <0>;
							};
						};
					};
				};

				power-domain@MT8189_POWER_DOMAIN_CSI_RX {
					reg = <MT8189_POWER_DOMAIN_CSI_RX>;
					#power-domain-cells = <0>;
				};

				power-domain@MT8189_POWER_DOMAIN_SSUSB {
					reg = <MT8189_POWER_DOMAIN_SSUSB>;
					mediatek,infracfg = <&infra_ao>;
					#power-domain-cells = <0>;
				};

				power-domain@MT8189_POWER_DOMAIN_PCIE {
					reg = <MT8189_POWER_DOMAIN_PCIE>;
					#address-cells = <1>;
					#size-cells = <0>;
					#power-domain-cells = <1>;

					power-domain@MT8189_POWER_DOMAIN_PCIE_PHY {
						reg = <MT8189_POWER_DOMAIN_PCIE_PHY>;
						#power-domain-cells = <0>;
					};
				};
			};
		};

		ssusb0: usb@11201000 {
			compatible = "mediatek,mt8189-mtu3", "mediatek,mtu3";
			reg = <0 0x11201000 0 0x2e00>, <0 0x11203e00 0 0x0100>;
			reg-names = "mac", "ippc";
			ranges = <0 0 0 0x11200000 0 0x3f00>;

			#address-cells = <2>;
			clocks = <&peri_ao CLK_PERAO_SSUSB0_SYS>,
				 <&peri_ao CLK_PERAO_SSUSB0_REF>,
				 <&peri_ao CLK_PERAO_SSUSB0_H>,
				 <&peri_ao CLK_PERAO_SSUSB0_F>,
				 <&peri_ao CLK_PERAO_SSUSB0_XHCI>,
				 <&peri_ao CLK_PERAO_SSUSB0_FRMCNT>;
			clock-names = "sys_ck", "ref_ck", "mcu_ck",
				      "dma_ck", "xhci_ck", "frmcnt_ck";
			interrupts = <GIC_SPI 384 IRQ_TYPE_LEVEL_HIGH 0>;
			#size-cells = <2>;
			phys = <&u2port0 PHY_TYPE_USB2>, <&u3port0 PHY_TYPE_USB3>;
			power-domains = <&spm MT8189_POWER_DOMAIN_SSUSB>;
			wakeup-source;
			mediatek,syscon-wakeup = <&peri_ao 0x214 110>;
			status = "disabled";

			xhci0: usb@0 {
				compatible =  "mediatek,mt8189-xhci", "mediatek,mtk-xhci";
				reg = <0 0 0 0x1000>;
				reg-names = "mac";
				interrupts = <GIC_SPI 385 IRQ_TYPE_LEVEL_HIGH 0>;
				clocks = <&peri_ao CLK_PERAO_SSUSB0_SYS>;
				clock-names = "sys_ck";
				status = "disabled";
			};
		};

		timer@1cc10000 {
			compatible = "mediatek,mt8189-timer", "mediatek,mt6765-timer";
			reg = <0 0x1cc10000 0 0x1000>;
			clocks = <&clk13m>;
			interrupts = <GIC_SPI 249 IRQ_TYPE_LEVEL_HIGH 0>;
		};

		u2phy1: xs-phy@11e90000 {
			compatible = "mediatek,mt8189-xsphy", "mediatek,xsphy";
			ranges = <0x0 0x0 0x11e90000 0x700>;
			#address-cells = <1>;
			#size-cells = <1>;
			status = "disabled";

			u2port1: usb-phy@0 {
				reg = <0x0 0x700>;
				clocks = <&topckgen CLK_TOP_USB2_PHY_RF_P1_EN>;
				clock-names = "ref";
				#phy-cells = <1>;
			};
		};

		u2phy2: xs-phy@11ef0000 {
			compatible = "mediatek,mt8189-xsphy", "mediatek,xsphy";
			ranges = <0x0 0x0 0x11ef0000 0x700>;
			#address-cells = <1>;
			#size-cells = <1>;
			status = "disabled";

			u2port2: usb-phy@0 {
				reg = <0 0x700>;
				clocks = <&topckgen CLK_TOP_USB2_PHY_RF_P2_EN>;
				clock-names = "ref";
				#phy-cells = <1>;
			};
		};

		u2phy4: xs-phy@11b10000 {
			compatible = "mediatek,mt8189-xsphy", "mediatek,xsphy";
			ranges = <0x0 0x0 0x11b10000 0x700>;
			#address-cells = <1>;
			#size-cells = <1>;
			status = "disabled";

			u2port4: usb-phy@0 {
				reg = <0x0 0x700>;
				clocks = <&topckgen CLK_TOP_USB2_PHY_RF_P4_EN>;
				clock-names = "ref";
				#phy-cells = <1>;
			};
		};

		u3phy0: xs-phy@11e80000 {
			compatible = "mediatek,mt8189-xsphy", "mediatek,xsphy";
			ranges = <0x0 0x0 0x11e80000 0x3900>;
			#address-cells = <1>;
			#size-cells = <1>;
			status = "disabled";

			u2port0: usb-phy@0 {
				reg = <0x0 0x400>;
				clocks = <&topckgen CLK_TOP_USB2_PHY_RF_P0_EN>;
				clock-names = "ref";
				#phy-cells = <1>;
			};

			u3port0: usb-phy@3400 {
				reg = <0x3400 0x500>;
				clocks = <&topckgen CLK_TOP_USB2_PHY_RF_P0_EN>;
				clock-names = "ref";
				#phy-cells = <1>;
			};
		};

		u3phy3: t-phy@11b00000 {
			compatible = "mediatek,mt8189-tphy", "mediatek,generic-tphy-v3";
			ranges = <0x0 0x0 0x11b00000 0x1000>;
			#address-cells = <1>;
			#size-cells = <1>;
			status = "disabled";

			u2port3: usb-phy@0 {
				reg = <0 0x400>;
				clocks = <&topckgen CLK_TOP_USB2_PHY_RF_P3_EN>;
				clock-names = "ref";
				#phy-cells = <1>;
			};

			u3port3: usb-phy@700 {
				reg = <0x700 0x700>;
				clocks = <&topckgen CLK_TOP_USB2_PHY_RF_P3_EN>;
				clock-names = "ref";
				#phy-cells = <1>;
			};
		};

		uart0: serial@11001000 {
			compatible = "mediatek,mt8189-uart", "mediatek,mt6577-uart";
			reg = <0 0x11001000 0 0x1000>;
			interrupts = <GIC_SPI 397 IRQ_TYPE_LEVEL_HIGH 0>;
			clocks = <&clk26m>, <&peri_ao CLK_PERAO_UART0>;
			clock-names = "baud", "bus";
			dmas = <&apdma 0>, <&apdma 1>;
			dma-names = "tx", "rx";
			status = "disabled";
		};

		uart1: serial@11002000 {
			compatible = "mediatek,mt8189-uart", "mediatek,mt6577-uart";
			reg = <0 0x11002000 0 0x1000>;
			interrupts = <GIC_SPI 398 IRQ_TYPE_LEVEL_HIGH 0>;
			clocks = <&clk26m>, <&peri_ao CLK_PERAO_UART1>;
			clock-names = "baud", "bus";
			dmas = <&apdma 2>, <&apdma 3>;
			dma-names = "tx", "rx";
			status = "disabled";
		};

		uart2: serial@11003000 {
			compatible = "mediatek,mt8189-uart", "mediatek,mt6577-uart";
			reg = <0 0x11003000 0 0x1000>;
			interrupts = <GIC_SPI 399 IRQ_TYPE_LEVEL_HIGH 0>;
			clocks = <&clk26m>, <&peri_ao CLK_PERAO_UART2>;
			clock-names = "baud", "bus";
			dmas = <&apdma 4>, <&apdma 5>;
			dma-names = "tx", "rx";
			status = "disabled";
		};

		uart3: serial@11004000 {
			compatible = "mediatek,mt8189-uart", "mediatek,mt6577-uart";
			reg = <0 0x11004000 0 0x1000>;
			interrupts = <GIC_SPI 457 IRQ_TYPE_LEVEL_HIGH 0>;
			clocks = <&clk26m>, <&peri_ao CLK_PERAO_UART3>;
			clock-names = "baud", "bus";
			dmas = <&apdma 6>, <&apdma 7>;
			dma-names = "tx", "rx";
			status = "disabled";
		};

		ufsphy: ufs-phy@112a0000 {
			compatible =  "mediatek,mt8189-ufsphy", "mediatek,mt8183-ufsphy";
			reg = <0 0x112a0000 0 0x10000>;
			clocks = <&ufscfg_ao CLK_UFSCFG_AO_REG_UNIPRO_SYS>,
				 <&ufscfg_ao CLK_UFSCFG_AO_REG_U_SAP_CFG>;
			clock-names = "unipro", "mp";
			#phy-cells = <0>;
			status = "disabled";
		};

		ufshci: ufshci@112b0000 {
			compatible = "mediatek,mt8189-ufshci";
			reg = <0 0x112b0000 0 0x2300>;
			clocks = <&ufscfg_pdn CLK_UFSCFG_REG_UFSHCI_UFS>,
				 <&ufscfg_pdn CLK_UFSCFG_REG_UFSHCI_AES>,
				 <&clk26m>,
				 <&ufscfg_ao CLK_UFSCFG_AO_REG_UNIPRO_SYS>,
				 <&clk26m>,
				 <&ufscfg_ao CLK_UFSCFG_AO_REG_U_PHY_TOP_AHB_S_BUS>,
				 <&ufscfg_ao CLK_UFSCFG_AO_REG_UNIPRO_TX_SYM>,
				 <&ufscfg_pdn CLK_UFSCFG_REG_UFSHCI_U_AXI>,
				 <&topckgen CLK_TOP_AES_UFSFDE_SEL>,
				 <&topckgen CLK_TOP_UNIVPLL_D6>,
				 <&topckgen CLK_TOP_MAINPLL_D4>,
				 <&ufscfg_ao CLK_UFSCFG_AO_REG_UNIPRO_RX_SYM0>,
				 <&ufscfg_ao CLK_UFSCFG_AO_REG_UNIPRO_RX_SYM1>,
				 <&ufscfg_pdn CLK_UFSCFG_REG_UFSHCI_U_AHB>,
				 <&clk26m>,
				 <&topckgen CLK_TOP_MSDCPLL_D2>;
			clock-names = "ufs",
				      "ufs_aes",
				      "ufs_tick",
				      "unipro_sysclk",
				      "unipro_tick",
				      "unipro_mp_bclk",
				      "ufs_tx_symbol",
				      "ufs_mem_sub",
				      "crypt_mux",
				      "crypt_lp",
				      "crypt_perf",
				      "ufs_rx_symbol0",
				      "ufs_rx_symbol1",
				      "ufs_sel",
				      "ufs_sel_min_src",
				      "ufs_sel_max_src";
			interrupts = <GIC_SPI 393 IRQ_TYPE_LEVEL_HIGH 0>;
			operating-points-v2 = <&ufs_opp_table>;
			phys = <&ufsphy>;
			resets = <&ufscfg_pdn MT8189_UFSPDN_RST_UFS_UNIPRO>,
				 <&ufscfg_pdn MT8189_UFSPDN_RST_UFS_CRYPTO>,
				 <&ufscfg_pdn MT8189_UFSPDN_RST_UFS_HCI>;
			reset-names = "unipro", "crypto", "hci";
			mediatek,ufs-disable-mcq;
			status = "disabled";
		};

		xhci1: usb@11210000 {
			compatible =  "mediatek,mt8189-xhci", "mediatek,mtk-xhci";
			reg = <0 0x11210000 0 0x1000>, <0 0x11213e00 0 0x0100>;
			reg-names = "mac", "ippc";

			clocks = <&peri_ao CLK_PERAO_SSUSB1_SYS>,
				 <&peri_ao CLK_PERAO_SSUSB1_REF>,
				 <&peri_ao CLK_PERAO_SSUSB1_H>,
				 <&peri_ao CLK_PERAO_SSUSB1_F>,
				 <&peri_ao CLK_PERAO_SSUSB1_XHCI>,
				 <&peri_ao CLK_PERAO_SSUSB1_FRMCNT>;
			clock-names = "sys_ck", "ref_ck", "mcu_ck",
				      "dma_ck", "xhci_ck", "frmcnt_ck";
			interrupts = <GIC_SPI 386 IRQ_TYPE_LEVEL_HIGH 0>;
			phys = <&u2port1 PHY_TYPE_USB2>;
			power-domains = <&spm MT8189_POWER_DOMAIN_SSUSB>;
			wakeup-source;
			mediatek,syscon-wakeup = <&peri_ao 0x21c 110>;
			status = "disabled";
		};

		xhci2: usb@11220000 {
			compatible =  "mediatek,mt8189-xhci", "mediatek,mtk-xhci";
			reg = <0 0x11220000 0 0x1000>, <0 0x11223e00 0 0x0100>;
			reg-names = "mac", "ippc";

			clocks = <&peri_ao CLK_PERAO_SSUSB2_SYS>,
				 <&peri_ao CLK_PERAO_SSUSB2_REF>,
				 <&peri_ao CLK_PERAO_SSUSB2_H>,
				 <&peri_ao CLK_PERAO_SSUSB2_F>,
				 <&peri_ao CLK_PERAO_SSUSB2_XHCI>,
				 <&peri_ao CLK_PERAO_SSUSB2_FRMCNT>;
			clock-names = "sys_ck", "ref_ck", "mcu_ck",
				      "dma_ck", "xhci_ck", "frmcnt_ck";
			interrupts = <GIC_SPI 472 IRQ_TYPE_LEVEL_HIGH 0>;
			phys = <&u2port2 PHY_TYPE_USB2>;
			power-domains = <&spm MT8189_POWER_DOMAIN_SSUSB>;
			wakeup-source;
			mediatek,syscon-wakeup = <&peri_ao 0x27c 110>;
			status = "disabled";
		};

		xhci3: usb@11260000 {
			compatible =  "mediatek,mt8189-xhci", "mediatek,mtk-xhci";
			reg = <0 0x11260000 0 0x2e00>, <0 0x11263e00 0 0x0100>;
			reg-names = "mac", "ippc";

			clocks = <&peri_ao CLK_PERAO_SSUSB3_SYS>,
				 <&peri_ao CLK_PERAO_SSUSB3_REF>,
				 <&peri_ao CLK_PERAO_SSUSB3_H>,
				 <&peri_ao CLK_PERAO_SSUSB3_F>,
				 <&peri_ao CLK_PERAO_SSUSB3_XHCI>,
				 <&peri_ao CLK_PERAO_SSUSB3_FRMCNT>;
			clock-names = "sys_ck", "ref_ck", "mcu_ck",
				      "dma_ck", "xhci_ck", "frmcnt_ck";
			interrupts = <GIC_SPI 473 IRQ_TYPE_LEVEL_HIGH 0>;
			phys = <&u2port3 PHY_TYPE_USB2>, <&u3port3 PHY_TYPE_USB3>;
			power-domains = <&spm MT8189_POWER_DOMAIN_SSUSB>;
			wakeup-source;
			mediatek,syscon-wakeup = <&peri_ao 0x284 110>;
			status = "disabled";
		};

		xhci4: usb@11270000 {
			compatible = "mediatek,mt8189-xhci", "mediatek,mtk-xhci";
			reg = <0 0x11270000 0 0x1000>, <0 0x11273e00 0 0x0100>;
			reg-names = "mac", "ippc";

			clocks = <&peri_ao CLK_PERAO_SSUSB4_SYS>,
				 <&peri_ao CLK_PERAO_SSUSB4_REF>,
				 <&peri_ao CLK_PERAO_SSUSB4_H>,
				 <&peri_ao CLK_PERAO_SSUSB4_F>,
				 <&peri_ao CLK_PERAO_SSUSB4_XHCI>,
				 <&peri_ao CLK_PERAO_SSUSB4_FRMCNT>;
			clock-names = "sys_ck", "ref_ck", "mcu_ck",
				      "dma_ck", "xhci_ck", "frmcnt_ck";
			interrupts = <GIC_SPI 474 IRQ_TYPE_LEVEL_HIGH 0>;
			phys = <&u2port4 PHY_TYPE_USB2>;
			power-domains = <&spm MT8189_POWER_DOMAIN_SSUSB>;
			wakeup-source;
			mediatek,syscon-wakeup = <&peri_ao 0x28c 110>;
			status = "disabled";
		};

		watchdog@1c00a000 {
			compatible = "mediatek,mt8189-wdt", "mediatek,mt6589-wdt";
			reg = <0 0x1c00a000 0 0x100>;
			#reset-cells = <1>;
		};
	};

	timer {
		compatible = "arm,armv8-timer";
		interrupt-parent = <&gic>;
		interrupts = <GIC_PPI 13 IRQ_TYPE_LEVEL_HIGH 0>,
			     <GIC_PPI 14 IRQ_TYPE_LEVEL_HIGH 0>,
			     <GIC_PPI 11 IRQ_TYPE_LEVEL_HIGH 0>,
			     <GIC_PPI 10 IRQ_TYPE_LEVEL_HIGH 0>;
	};
};
